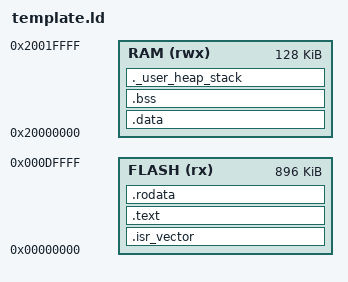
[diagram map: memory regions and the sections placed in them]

ENTRY(Reset_Handler)

_Min_Heap_Size = 0x200; /* required amount of heap */
_Min_Stack_Size = 0x400; /* required amount of stack */

MEMORY
{
    FLASH(rx) : ORIGIN = 0x00, LENGTH = 0xE0000
    RAM (rwx) : ORIGIN = 0x20000000, LENGTH = 0x20000 
}

SECTIONS
{
    .isr_vector :
    {
        . = ALIGN(4);
        KEEP(*(.isr_vector))
        . = ALIGN(4);
    } >FLASH

    .text :
    {
        . = ALIGN(4);
        *(.text)           /* .text sections (code) */
        *(.text*)          /* .text* sections (code) */
        *(.glue_7)         /* glue arm to thumb code */
        *(.glue_7t)        /* glue thumb to arm code */
        *(.eh_frame)

        KEEP (*(.init))
        KEEP (*(.fini))

        . = ALIGN(4);
        _etext = .;        /* define a global symbols at end of code */
    } >FLASH

    /* Constant data into "FLASH" Rom type memory */
    .rodata :
    {
        . = ALIGN(4);
        *(.rodata)         /* .rodata sections (constants, strings, etc.) */
        *(.rodata*)        /* .rodata* sections (constants, strings, etc.) */
        . = ALIGN(4);
    } >FLASH

    _sidata = LOADADDR(.data);

    .data : 
    {
        _sdata = .;
        *(.data)
        *(.data.*)
        _edata = .;
    } >RAM

    .bss :
    {
        _sbss = .;
        *(.bss)
        *(.bss.*)
        _ebss = .;
    } >RAM

    /* User_heap_stack section, used to check that there is enough "RAM" Ram  type memory left */
    ._user_heap_stack :
    {
        . = ALIGN(8);
        PROVIDE ( end = . );
        PROVIDE ( _end = . );
        . = . + _Min_Heap_Size;
        . = . + _Min_Stack_Size;
        . = ALIGN(8);
    } >RAM

    _estack = ORIGIN(RAM) + LENGTH(RAM);
}


